# slm32x030 register map
Vendor: Keil; File version: 1.0.1
CPU: CM0 r2p1, little endian, no MPU, no FPU, 4 interrupt priority bits
Registers are 32-bit, read-write, reset 0x0 unless marked. A register's access mark holds for its fields unless they carry their own. Offsets are from the block's base; [hi:lo] are bit positions.

## RCMU
Base 0x40021000
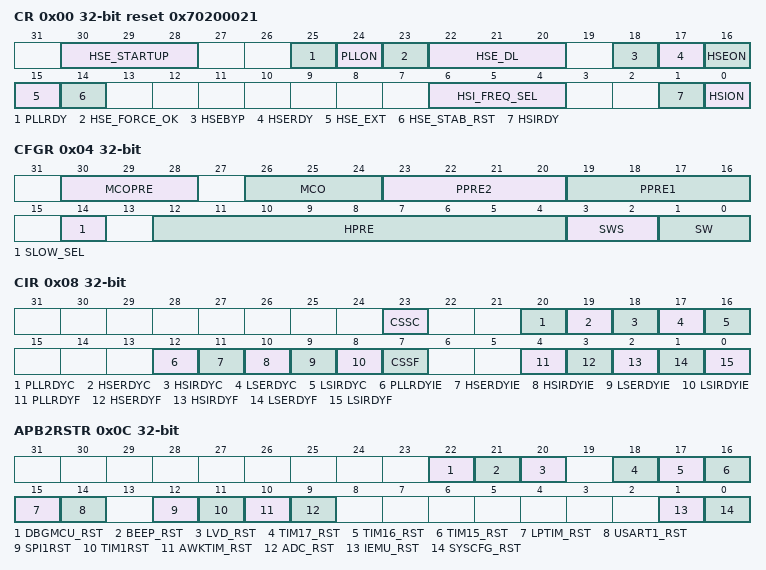
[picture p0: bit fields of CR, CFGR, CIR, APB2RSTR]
0x00 CR access per field reset 0x70200021 — RCMU_CR
  [30:28] HSE_STARTUP rw — Later Add Description
  [25] PLLRDY ro — Later Add Description
  [24] PLLON rw — Later Add Description
  [23] HSE_FORCE_OK rw — Later Add Description
  [22:20] HSE_DL rw — Later Add Description
  [18] HSEBYP rw — Later Add Description
  [17] HSERDY ro — Later Add Description
  [16] HSEON rw — Later Add Description
  [15] HSE_EXT rw — Later Add Description
  [14] HSE_STAB_RST rw — Later Add Description
  [6:4] HSI_FREQ_SEL rw — Later Add Description
  [1] HSIRDY ro — Later Add Description
  [0] HSION rw — Later Add Description
0x04 CFGR access per field — RCMU_CFGR
  [30:28] MCOPRE rw — Later Add Description
  [26:24] MCO rw — Later Add Description
  [23:20] PPRE2 rw — Later Add Description
  [19:16] PPRE1 rw — Later Add Description
  [14] SLOW_SEL rw — Later Add Description
  [12:4] HPRE rw — Later Add Description
  [3:2] SWS ro — Later Add Description
  [1:0] SW rw — Later Add Description
0x08 CIR access per field — RCMU_CIR
  [23] CSSC wo — Later Add Description
  [20] PLLRDYC wo — Later Add Description
  [19] HSERDYC wo — Later Add Description
  [18] HSIRDYC wo — Later Add Description
  [17] LSERDYC wo — Later Add Description
  [16] LSIRDYC wo — Later Add Description
  [12] PLLRDYIE rw — Later Add Description
  [11] HSERDYIE rw — Later Add Description
  [10] HSIRDYIE rw — Later Add Description
  [9] LSERDYIE rw — Later Add Description
  [8] LSIRDYIE rw — Later Add Description
  [7] CSSF ro — Later Add Description
  [4] PLLRDYF ro — Later Add Description
  [3] HSERDYF ro — Later Add Description
  [2] HSIRDYF ro — Later Add Description
  [1] LSERDYF ro — Later Add Description
  [0] LSIRDYF ro — Later Add Description
0x0C APB2RSTR access per field — RCMU_APB2RSTR
  [22] DBGMCU_RST rw — Later Add Description
  [21] BEEP_RST rw — Later Add Description
  [20] LVD_RST rw — Later Add Description
  [18] TIM17_RST rw — Later Add Description
  [17] TIM16_RST rw — Later Add Description
  [16] TIM15_RST rw — Later Add Description
  [15] LPTIM_RST rw — Later Add Description
  [14] USART1_RST rw — Later Add Description
  [12] SPI1RST rw — Later Add Description
  [11] TIM1RST rw — Later Add Description
  [10] AWKTIM_RST rw — Later Add Description
  [9] ADC_RST rw — Later Add Description
  [1] IEMU_RST ro — Later Add Description
  [0] SYSCFG_RST rw — Later Add Description
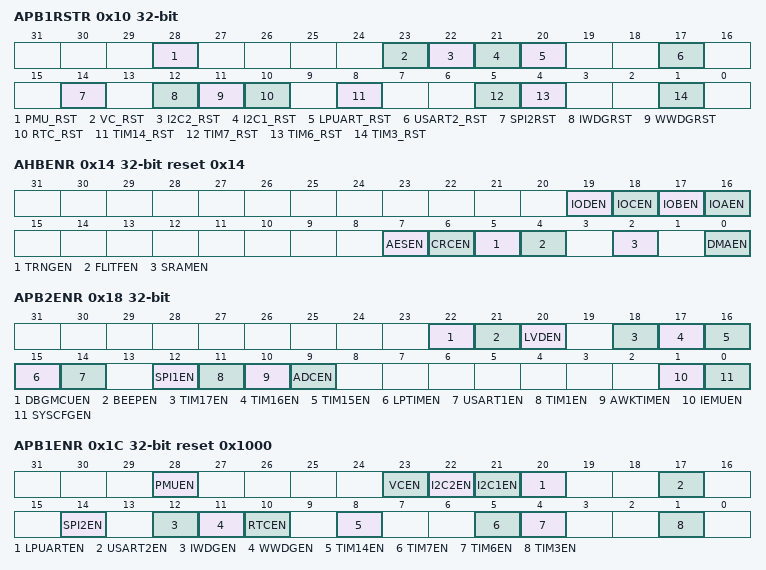
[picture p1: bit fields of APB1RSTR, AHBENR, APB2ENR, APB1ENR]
0x10 APB1RSTR — RCMU_APB1RSTR
  [28] PMU_RST — Later Add Description
  [23] VC_RST — Later Add Description
  [22] I2C2_RST — Later Add Description
  [21] I2C1_RST — Later Add Description
  [20] LPUART_RST — Later Add Description
  [17] USART2_RST — Later Add Description
  [14] SPI2RST — Later Add Description
  [12] IWDGRST — Later Add Description
  [11] WWDGRST — Later Add Description
  [10] RTC_RST — Later Add Description
  [8] TIM14_RST — Later Add Description
  [5] TIM7_RST — Later Add Description
  [4] TIM6_RST — Later Add Description
  [1] TIM3_RST — Later Add Description
0x14 AHBENR reset 0x14 — RCMU_AHBENR
  [19] IODEN — Later Add Description
  [18] IOCEN — Later Add Description
  [17] IOBEN — Later Add Description
  [16] IOAEN — Later Add Description
  [7] AESEN — Later Add Description
  [6] CRCEN — Later Add Description
  [5] TRNGEN — Later Add Description
  [4] FLITFEN — Later Add Description
  [2] SRAMEN — Later Add Description
  [0] DMAEN — Later Add Description
0x18 APB2ENR — RCMU_APB2ENR
  [22] DBGMCUEN — Later Add Description
  [21] BEEPEN — Later Add Description
  [20] LVDEN — Later Add Description
  [18] TIM17EN — Later Add Description
  [17] TIM16EN — Later Add Description
  [16] TIM15EN — Later Add Description
  [15] LPTIMEN — Later Add Description
  [14] USART1EN — Later Add Description
  [12] SPI1EN — Later Add Description
  [11] TIM1EN — Later Add Description
  [10] AWKTIMEN — Later Add Description
  [9] ADCEN — Later Add Description
  [1] IEMUEN — Later Add Description
  [0] SYSCFGEN — Later Add Description
0x1C APB1ENR reset 0x1000 — RCMU_APB1ENR
  [28] PMUEN — Later Add Description
  [23] VCEN — Later Add Description
  [22] I2C2EN — Later Add Description
  [21] I2C1EN — Later Add Description
  [20] LPUARTEN — Later Add Description
  [17] USART2EN — Later Add Description
  [14] SPI2EN — Later Add Description
  [12] IWDGEN — Later Add Description
  [11] WWDGEN — Later Add Description
  [10] RTCEN — Later Add Description
  [8] TIM14EN — Later Add Description
  [5] TIM7EN — Later Add Description
  [4] TIM6EN — Later Add Description
  [1] TIM3EN — Later Add Description
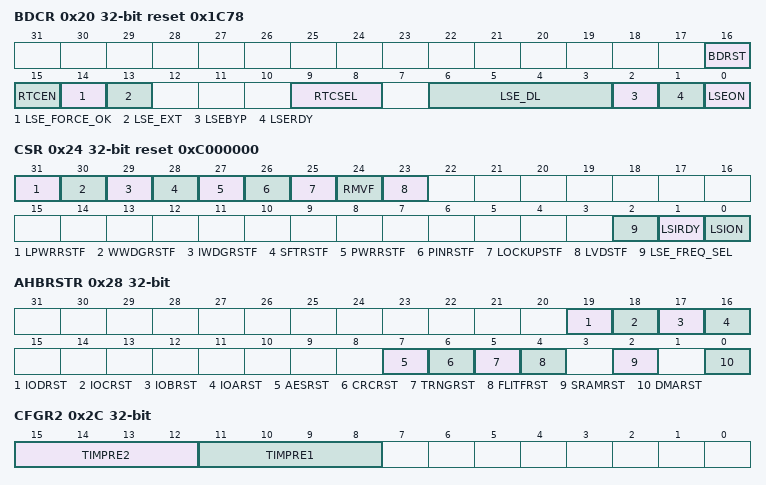
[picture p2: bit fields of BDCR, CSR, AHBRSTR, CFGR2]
0x20 BDCR access per field reset 0x1C78 — RCMU_BDCR
  [16] BDRST rw — Later Add Description
  [15] RTCEN rw — Later Add Description
  [14] LSE_FORCE_OK rw — Later Add Description
  [13] LSE_EXT rw — Later Add Description
  [9:8] RTCSEL rw — Later Add Description
  [6:3] LSE_DL rw — Later Add Description
  [2] LSEBYP rw — Later Add Description
  [1] LSERDY ro — Later Add Description
  [0] LSEON rw — Later Add Description
0x24 CSR access per field reset 0xC000000 — RCMU_CSR
  [31] LPWRRSTF ro — Later Add Description
  [30] WWDGRSTF ro — Later Add Description
  [29] IWDGRSTF ro — Later Add Description
  [28] SFTRSTF ro — Later Add Description
  [27] PWRRSTF ro — Later Add Description
  [26] PINRSTF ro — Later Add Description
  [25] LOCKUPSTF ro — Later Add Description
  [24] RMVF rw — Later Add Description
  [23] LVDSTF ro — Later Add Description
  [2] LSE_FREQ_SEL ro — Later Add Description
  [1] LSIRDY ro — Later Add Description
  [0] LSION rw — Later Add Description
0x28 AHBRSTR — RCMU_AHBRSTR
  [19] IODRST — Later Add Description
  [18] IOCRST — Later Add Description
  [17] IOBRST — Later Add Description
  [16] IOARST — Later Add Description
  [7] AESRST — Later Add Description
  [6] CRCRST — Later Add Description
  [5] TRNGRST — Later Add Description
  [4] FLITFRST — Later Add Description
  [2] SRAMRST — Later Add Description
  [0] DMARST — Later Add Description
0x2C CFGR2 ro — RCMU_CFGR2
  [15:12] TIMPRE2 — Later Add Description
  [11:8] TIMPRE1 — Later Add Description
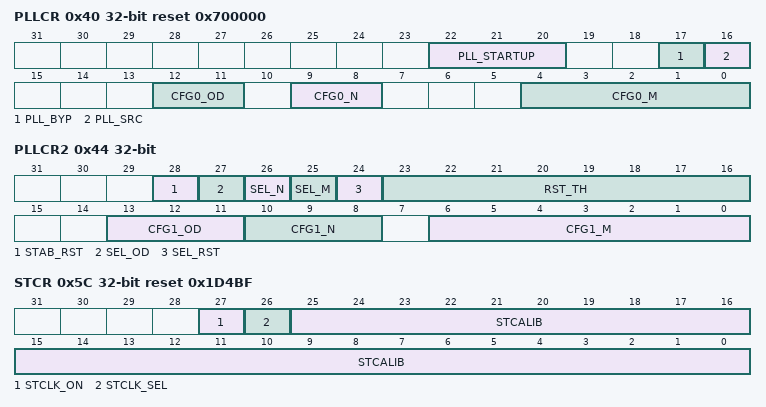
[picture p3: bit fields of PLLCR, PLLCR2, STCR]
0x40 PLLCR access not given reset 0x700000 — RCMU_PLLCR
  [22:20] PLL_STARTUP rw — Later Add Description
  [17] PLL_BYP rw — Later Add Description
  [16] PLL_SRC rw — Later Add Description
  [12:11] CFG0_OD — Later Add Description
  [9:8] CFG0_N — Later Add Description
  [4:0] CFG0_M — Later Add Description
0x44 PLLCR2 — RCMU_PLLCR2
  [28] STAB_RST — Later Add Description
  [27] SEL_OD — Later Add Description
  [26] SEL_N — Later Add Description
  [25] SEL_M — Later Add Description
  [24] SEL_RST — Later Add Description
  [23:16] RST_TH — Later Add Description
  [13:11] CFG1_OD — Later Add Description
  [10:8] CFG1_N — Later Add Description
  [6:0] CFG1_M — Later Add Description
0x5C STCR reset 0x1D4BF — RCMU_STCR
  [27] STCLK_ON — Later Add Description
  [26] STCLK_SEL — Later Add Description
  [25:0] STCALIB — Later Add Description
0x60 IRQLATENCY — RCMU_IRQLATENCY
  [7:0] irqlatency — Later Add Description
